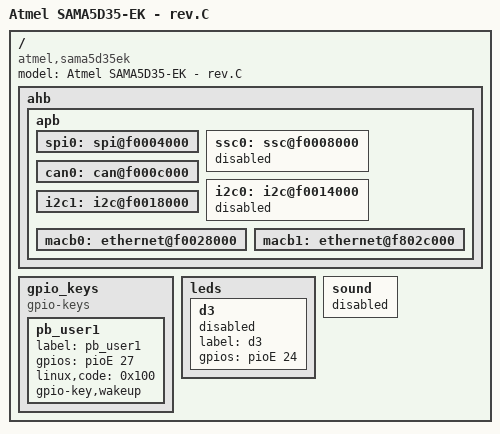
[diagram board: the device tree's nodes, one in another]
/*
 * sama5d35ek_revc.dts - Device Tree file for SAMA5D35-EK up to rev.C MB
 *
 *  Copyright (C) 2013 Atmel,
 *                2013 Ludovic Desroches <ludovic.desroches@atmel.com>
 *
 * Licensed under GPLv2 or later.
 */
/dts-v1/;
#include "sama5d35.dtsi"
#include "sama5d3xmb.dtsi"
/* #include "sama5d3xmb_revc_audio.dtsi" */	/* require i2c0 */
#include "sama5d3xmb_isi_sensors.dtsi"	/* Conflict with i2c0 & led d3 */

/ {
	model = "Atmel SAMA5D35-EK - rev.C";
	compatible = "atmel,sama5d35ek", "atmel,sama5d3xmb", "atmel,sama5d3xcm", "atmel,sama5d35", "atmel,sama5d3", "atmel,sama5";

	ahb {
		apb {
			spi0: spi@f0004000 {
				status = "okay";
			};

			ssc0: ssc@f0008000 {
				status = "disabled";
			};

			can0: can@f000c000 {
				status = "okay";
			};

			i2c0: i2c@f0014000 {
				status = "disabled";
			};

			i2c1: i2c@f0018000 {
				status = "okay";
			};

			macb0: ethernet@f0028000 {
				status = "okay";
			};

			macb1: ethernet@f802c000 {
				status = "okay";
			};
		};
	};

	/* Conflict with LCD pins */
	gpio_keys {
		compatible = "gpio-keys";
		#address-cells = <1>;
		#size-cells = <0>;

		pb_user1 {
			label = "pb_user1";
			gpios = <&pioE 27 GPIO_ACTIVE_HIGH>;
			linux,code = <0x100>;
			gpio-key,wakeup;
		};
	};

	leds {
		d3 {
			label = "d3";
			gpios = <&pioE 24 GPIO_ACTIVE_HIGH>;
			status = "disabled";
		};
	};

	sound {
		status = "disable";
	};
};
